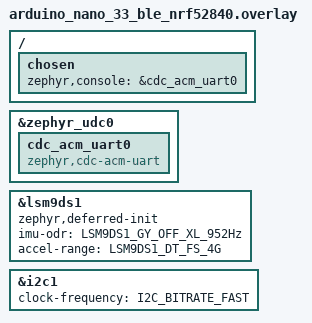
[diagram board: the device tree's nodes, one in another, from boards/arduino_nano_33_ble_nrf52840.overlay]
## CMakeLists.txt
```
# SPDX-License-Identifier: Apache-2.0
cmake_minimum_required(VERSION 3.20.0)

find_package(Zephyr REQUIRED HINTS $ENV{ZEPHYR_BASE})
project(vibration_monitor)

target_sources(app PRIVATE src/main.c src/accel_stats.c src/vib_fft.c src/ble_fmt.c src/ble_vib.c src/ble_sec.c src/ble_cmd.c)
```

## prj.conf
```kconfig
# Console over USB (CDC ACM), following Zephyr v4.4's samples/subsys/usb/console
CONFIG_GPIO=y
CONFIG_SERIAL=y
CONFIG_CONSOLE=y
CONFIG_UART_CONSOLE=y
CONFIG_STDOUT_CONSOLE=y
CONFIG_UART_LINE_CTRL=y

CONFIG_USB_DEVICE_STACK_NEXT=y
CONFIG_CDC_ACM_SERIAL_INITIALIZE_AT_BOOT=y
CONFIG_CDC_ACM_SERIAL_PRODUCT_STRING="Vibration monitor"

# Motion sensor (LSM9DS1, started by main.c with device_init)
CONFIG_SENSOR=y
CONFIG_I2C=y
CONFIG_REGULATOR=y

# FFT: CMSIS-DSP real FFT on the Cortex-M4F's floating-point unit
CONFIG_CMSIS_DSP=y
CONFIG_CMSIS_DSP_TRANSFORM=y
CONFIG_FPU=y
CONFIG_FPU_SHARING=y

# Bluetooth LE peripheral (custom GATT service in src/ble_vib.c)
CONFIG_BT=y
CONFIG_BT_PERIPHERAL=y
CONFIG_BT_DEVICE_NAME="VibMon Nano33"

# BLE security (step 8a): authenticated LE Secure Connections, passkey shown on
# the USB console.
CONFIG_BT_SMP=y
# Secure Connections Only mode: selects BT_SMP_SC_PAIR_ONLY, requires security
# level 4 and makes smp.c reject Just Works (unauthenticated) pairing.
CONFIG_BT_SMP_SC_ONLY=y
CONFIG_BT_SMP_ENFORCE_MITM=y
CONFIG_BT_BONDABLE=y
# Two phones may be paired; a third (who also needs the passkey) replaces the oldest.
CONFIG_BT_MAX_PAIRED=2
CONFIG_BT_KEYS_OVERWRITE_OLDEST=y
# Precaution (not measured): pairing callbacks run on the BT RX thread and print.
CONFIG_BT_RX_STACK_SIZE=2048

# Step 8b: pairing keys survive RESET. Settings stored with NVS in the board's
# free storage_partition (0xF8000, 32 KB), as in Zephyr's peripheral_hids sample.
CONFIG_BT_SETTINGS=y
CONFIG_SETTINGS=y
CONFIG_FLASH=y
CONFIG_FLASH_MAP=y
CONFIG_NVS=y
# Settings are written from the system work queue (the HIDS sample raises it too).
CONFIG_SYSTEM_WORKQUEUE_STACK_SIZE=2048

# Never enable CONFIG_BT_FIXED_PASSKEY or CONFIG_BT_SMP_ALLOW_UNAUTH_OVERWRITE:
# ble_sec.c refuses to build with the first.

# Threads: the sampler (priority 2) pre-empts the analysis in main (priority 7)
CONFIG_MAIN_THREAD_PRIORITY=7
# 3072 since step 8b: settings_load() (NVS) runs on this thread. Precaution, not measured.
CONFIG_MAIN_STACK_SIZE=3072

# No CONFIG_LOG: with the console on USB, immediate-mode logging from the USB
# stack itself goes through the USB link being set up.
```

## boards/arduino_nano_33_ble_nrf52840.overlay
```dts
/*
 * Board overlay for the Arduino Nano 33 BLE (rev1).
 *
 * 1. Console over USB (CDC ACM) instead of the UART on the header pins.
 *    Same pattern as Zephyr's snippets/cdc-acm-console; the board file
 *    already enables the USB device (zephyr_udc0 = &usbd).
 * 2. LSM9DS1 accelerometer ON. The binding's default output data rate is the
 *    power-up configuration, which is "IMU off" (0x00): without this the
 *    accelerometer reads zeros. Accelerometer 952 Hz (the application reads
 *    it at 400 Hz, so every read gets a fresh sample), gyroscope off, +-4 g.
 *    I2C at 400 kHz so one 6-byte read takes a fraction of the 2.5 ms period.
 * 3. zephyr,deferred-init: the driver is NOT started automatically at boot.
 *    main.c starts it with device_init() after the sensor supply has settled,
 *    and reports the result. (Started at boot it failed: "LSM9DS1 NOT READY".)
 */
#include <zephyr/dt-bindings/i2c/i2c.h>
#include <zephyr/dt-bindings/sensor/lsm9ds1.h>

/ {
	chosen {
		zephyr,console = &cdc_acm_uart0;
	};
};

&zephyr_udc0 {
	cdc_acm_uart0: cdc_acm_uart0 {
		compatible = "zephyr,cdc-acm-uart";
	};
};

&lsm9ds1 {
	zephyr,deferred-init;
	imu-odr = <LSM9DS1_GY_OFF_XL_952Hz>;
	accel-range = <LSM9DS1_DT_FS_4G>;
};

&i2c1 {
	clock-frequency = <I2C_BITRATE_FAST>;
};
```

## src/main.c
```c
/*
 * zephyr-ble-vibration-monitor - step 8: dominant vibration frequency (FFT),
 * sent over BLE (ble_vib.c) to paired phones only (ble_sec.c) as well as
 * printed on the USB console.
 *
 * Threads:
 *  - sampler (priority 2): reads the LSM9DS1 every 2.5 ms (400 Hz) from a
 *    kernel timer into one of two buffers (ping-pong). When a block of 512
 *    samples is full it hands the buffer to main through a message queue and
 *    carries on in the other buffer. It records the real sample rate, missed
 *    timer ticks, read errors and the slowest sensor read.
 *  - main (priority 7): start-up report, then for each block: CMSIS-DSP FFT
 *    (vib_fft.c), dominant frequency, amplitude and rms, printed over USB.
 * Block = 512 samples = 1.28 s; resolution 0.78 Hz; highest frequency 200 Hz.
 */
#include <stdbool.h>
#include <stdlib.h>
#include <zephyr/kernel.h>
#include <zephyr/device.h>
#include <zephyr/sys/atomic.h>
#include <zephyr/drivers/gpio.h>
#include <zephyr/drivers/i2c.h>
#include <zephyr/drivers/regulator.h>
#include <zephyr/drivers/sensor.h>
#include <zephyr/drivers/uart.h>
#include <zephyr/sys/printk.h>
#include <zephyr/version.h>
#include "vib_fft.h"
#include "ble_vib.h"

BUILD_ASSERT(DT_NODE_HAS_COMPAT(DT_CHOSEN(zephyr_console), zephyr_cdc_acm_uart),
	     "The console must be the USB CDC ACM UART (see the board overlay)");

#define SAMPLE_PERIOD_US 2500     /* 400 Hz */
#define HOST_WAIT_MS     30000    /* wait for a terminal at start-up */
#define MIN_FREQ_HZ      2.0f     /* ignore slow tilting and drift */
#define STILL_RMS        0.05f    /* m/s^2: below this the board counts as still */
#define SAMPLER_PRIO     2
#define SAMPLER_STACK    1024

#define IMU_NODE DT_NODELABEL(lsm9ds1)

static const struct gpio_dt_spec led = GPIO_DT_SPEC_GET(DT_ALIAS(led0), gpios);
static const struct device *const imu = DEVICE_DT_GET(IMU_NODE);
static const struct device *const i2c_bus = DEVICE_DT_GET(DT_BUS(IMU_NODE));
static const struct device *const vdd_env = DEVICE_DT_GET(DT_NODELABEL(vdd_env));

/* ---------------- shared between the sampler and main ---------------- */
struct block_info {
	int64_t ticks;          /* time from first to last sample, in system ticks */
	uint32_t errors;        /* failed sensor reads (previous value repeated) */
	uint32_t missed;        /* timer ticks the sampler was too late for */
	uint32_t max_read_us;   /* slowest sensor read in the block */
};

static int32_t raw[2][3][VIB_N];          /* milli-m/s^2 */
static struct block_info info[2];
static atomic_t busy[2];                   /* set while main owns the buffer */
static atomic_t overruns;                  /* blocks dropped because main was late */
K_MSGQ_DEFINE(block_q, sizeof(uint8_t), 2, 1);
K_TIMER_DEFINE(sample_timer, NULL, NULL);
K_THREAD_STACK_DEFINE(sampler_stack, SAMPLER_STACK);
static struct k_thread sampler_thread;

static int32_t to_milli(const struct sensor_value *v)
{
	return v->val1 * 1000 + v->val2 / 1000;
}

static void sampler(void *p1, void *p2, void *p3)
{
	ARG_UNUSED(p1); ARG_UNUSED(p2); ARG_UNUSED(p3);
	uint8_t w = 0;                 /* buffer being filled */
	bool storing = true;           /* false while both buffers are owned by main */
	uint32_t i = 0;
	int32_t last[3] = { 0, 0, 0 };
	int64_t t_first = 0;
	struct block_info cur = { 0 };

	k_timer_start(&sample_timer, K_USEC(SAMPLE_PERIOD_US), K_USEC(SAMPLE_PERIOD_US));
	while (1) {
		struct sensor_value v[3];
		uint32_t expired = k_timer_status_sync(&sample_timer);
		uint32_t c0 = k_cycle_get_32();

		if (expired > 1) {
			cur.missed += expired - 1;
		}
		if (sensor_sample_fetch_chan(imu, SENSOR_CHAN_ACCEL_XYZ) == 0 &&
		    sensor_channel_get(imu, SENSOR_CHAN_ACCEL_XYZ, v) == 0) {
			for (int a = 0; a < 3; a++) {
				last[a] = to_milli(&v[a]);
			}
		} else {
			cur.errors++;
		}
		uint32_t us = k_cyc_to_us_floor32(k_cycle_get_32() - c0);

		if (us > cur.max_read_us) {
			cur.max_read_us = us;
		}

		int64_t now = k_uptime_ticks();

		if (i == 0) {
			t_first = now;
		}
		if (storing) {
			for (int a = 0; a < 3; a++) {
				raw[w][a][i] = last[a];
			}
		}
		if (++i < VIB_N) {
			continue;
		}

		/* block complete */
		if (storing) {
			cur.ticks = now - t_first;
			info[w] = cur;
			atomic_set(&busy[w], 1);
			(void)k_msgq_put(&block_q, &w, K_NO_WAIT);
		} else {
			atomic_inc(&overruns);
		}
		uint8_t next = w ^ 1U;

		if (atomic_get(&busy[next]) == 0) {
			w = next;
			storing = true;
		} else {
			storing = false;   /* main still has both: skip this block */
		}
		i = 0;
		cur = (struct block_info){ 0 };
	}
}

/* ---------------- main: start-up report and analysis ---------------- */
static bool host_connected(const struct device *console)
{
	uint32_t dtr = 0;

	(void)uart_line_ctrl_get(console, UART_LINE_CTRL_DTR, &dtr);
	return dtr != 0;
}

/* prints v with 1 or 3 decimals, e.g. -0.512 */
static void print_f(float v, int decimals)
{
	long long scale = (decimals == 1) ? 10 : 1000;
	long long s = (long long)(v * (float)scale + (v >= 0.0f ? 0.5f : -0.5f));
	long long whole = llabs(s) / scale, frac = llabs(s) % scale;

	if (decimals == 1) {
		printk("%s%lld.%01lld", s < 0 ? "-" : "", whole, frac);
	} else {
		printk("%s%lld.%03lld", s < 0 ? "-" : "", whole, frac);
	}
}

static void probe(const char *name, uint16_t addr, uint8_t expect)
{
	uint8_t id = 0;
	int ret = i2c_reg_read_byte(i2c_bus, addr, 0x0F, &id);

	printk("  I2C 0x%02X %-13s WHO_AM_I: ", addr, name);
	if (ret == 0) {
		printk("0x%02X %s\n", id, id == expect ? "(correct)" : "(UNEXPECTED)");
	} else {
		printk("no answer (error %d)\n", ret);
	}
}

static bool start_sensor(void)
{
	int ret;

	printk("Sensor start-up report:\n");
	printk("  I2C bus %s: %s\n", i2c_bus->name, device_is_ready(i2c_bus) ? "ready" : "NOT READY");
	printk("  sensor supply (vdd_env): %s\n",
	       !device_is_ready(vdd_env) ? "regulator NOT READY" :
	       (regulator_is_enabled(vdd_env) ? "on" : "OFF"));
	probe("accel/gyro", 0x6B, 0x68);
	probe("magnetometer", 0x1E, 0x3D);
	ret = device_init(imu);
	printk("  device_init(lsm9ds1): %d %s\n", ret, ret == 0 ? "(started)" : "(FAILED)");
	return ret == 0 && device_is_ready(imu);
}

static void print_header(void)
{
	printk("every %u ms: dominant frequency | amplitude | rms (m/s^2) | real rate | fft time | "
	       "slowest read | missed / errors / dropped\n",
	       (unsigned int)(VIB_N * SAMPLE_PERIOD_US / 1000U));
}

int main(void)
{
	const struct device *const console = DEVICE_DT_GET(DT_CHOSEN(zephyr_console));
	bool led_ok = gpio_is_ready_dt(&led) &&
		      gpio_pin_configure_dt(&led, GPIO_OUTPUT_INACTIVE) == 0;
	static float fbuf[3][VIB_N];
	const float *const axes[3] = { fbuf[0], fbuf[1], fbuf[2] };
	bool host_seen;

	for (int waited = 0; waited < HOST_WAIT_MS && !host_connected(console); waited += 100) {
		if (led_ok && (waited % 500) == 0) {
			(void)gpio_pin_toggle_dt(&led);
		}
		k_msleep(100);
	}
	host_seen = host_connected(console);

	printk("\n=== zephyr-ble-vibration-monitor, step 8b ===\n");
	printk("Zephyr %s on %s, uptime %lld ms\n", KERNEL_VERSION_STRING, CONFIG_BOARD,
	       (long long)k_uptime_get());
	if (!start_sensor()) {
		printk("LSM9DS1 NOT READY - stopping here (see the report above)\n");
		return 0;
	}
	if (vib_fft_init() != VIB_OK) {
		printk("CMSIS-DSP FFT init FAILED - stopping here\n");
		return 0;
	}
	printk("LSM9DS1 READY. Sampling 400 Hz, blocks of %d (1.28 s), resolution 0.78 Hz, "
	       "up to 200 Hz; still below rms ", VIB_N);
	print_f(STILL_RMS, 3);
	printk(" m/s^2\n");
	int ble_err = ble_vib_init();

	if (ble_err == 0) {
		printk("BLE advertising as \"%s\" (service 5f2e0001-6d1b-4a3c-9b2e-7c4d1a2b3c4d)\n",
		       CONFIG_BT_DEVICE_NAME);
	} else {
		printk("BLE start FAILED (error %d) - continuing without it\n", ble_err);
	}
	print_header();

	k_thread_create(&sampler_thread, sampler_stack, K_THREAD_STACK_SIZEOF(sampler_stack),
			sampler, NULL, NULL, NULL, SAMPLER_PRIO, 0, K_NO_WAIT);
	k_thread_name_set(&sampler_thread, "sampler");

	uint16_t seq = 0;
	enum ble_vib_state ble_prev = BLE_VIB_OFF;

	while (1) {
		uint8_t b;
		struct block_info bi;
		struct vib_result r;
		enum ble_vib_state ble_now = ble_prev;   /* unchanged unless published */

		(void)k_msgq_get(&block_q, &b, K_FOREVER);
		for (int a = 0; a < 3; a++) {
			for (int i = 0; i < VIB_N; i++) {
				fbuf[a][i] = (float)raw[b][a][i] / 1000.0f;
			}
		}
		bi = info[b];
		atomic_set(&busy[b], 0);           /* copied: the sampler may reuse it */

		float fs = (bi.ticks > 0) ?
			(float)(VIB_N - 1) * (float)CONFIG_SYS_CLOCK_TICKS_PER_SEC / (float)bi.ticks : 0.0f;
		uint32_t c0 = k_cycle_get_32();
		int ret = vib_fft_analyse(axes, VIB_N, fs, MIN_FREQ_HZ, STILL_RMS, &r);
		uint32_t fft_us = k_cyc_to_us_floor32(k_cycle_get_32() - c0);

		if (ret == VIB_OK) {
			ble_now = ble_vib_publish(&r, seq++);
		}
		if (led_ok) {
			(void)gpio_pin_toggle_dt(&led);
		}
		if (!host_connected(console)) {
			ble_prev = ble_now;
			host_seen = false;
			continue;
		}
		if (!host_seen) {
			host_seen = true;
			printk("\n(terminal connected)\n");
			print_header();
		}
		if (ble_now != ble_prev) {
			printk("BLE: %s\n", ble_vib_state_str(ble_now));
			ble_prev = ble_now;
		}
		if (ret != VIB_OK) {
			printk("analysis error %d (rate ", ret);
			print_f(fs, 1);
			printk(" Hz)\n");
			continue;
		}
		if (r.active) {
			printk("f ");
			print_f(r.freq_hz, 1);
			printk(" Hz | amp ");
			print_f(r.amp, 3);
			printk(" | rms ");
			print_f(r.rms, 3);
		} else {
			printk("still        | rms ");
			print_f(r.rms, 3);
		}
		printk(" | ");
		print_f(fs, 1);
		printk(" Hz | fft %u us | read %u us | %u/%u/%u\n", (unsigned int)fft_us,
		       (unsigned int)bi.max_read_us, (unsigned int)bi.missed, (unsigned int)bi.errors,
		       (unsigned int)atomic_get(&overruns));
	}
	return 0;
}
```

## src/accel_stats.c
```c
/* accel_stats.c - see accel_stats.h */
#include "accel_stats.h"

uint32_t accel_isqrt64(uint64_t v)
{
	/* bit-by-bit method: exact, no floating point, bounded time */
	uint64_t res = 0;
	uint64_t bit = (uint64_t)1 << 62;

	while (bit > v) {
		bit >>= 2;
	}
	while (bit != 0) {
		if (v >= res + bit) {
			v -= res + bit;
			res = (res >> 1) + bit;
		} else {
			res >>= 1;
		}
		bit >>= 2;
	}
	return (uint32_t)res;
}

int32_t accel_magnitude(const int32_t v[3])
{
	uint64_t sq = 0;

	for (int i = 0; i < 3; i++) {
		int64_t c = v[i];
		sq += (uint64_t)(c * c);
	}
	return (int32_t)accel_isqrt64(sq);
}

void accel_stats_reset(struct accel_stats *s)
{
	for (int i = 0; i < 3; i++) {
		s->sum[i] = 0;
	}
	s->n = 0;
	s->mag_min = INT32_MAX;
	s->mag_max = 0;
}

void accel_stats_add(struct accel_stats *s, const int32_t v[3])
{
	int32_t m = accel_magnitude(v);

	for (int i = 0; i < 3; i++) {
		s->sum[i] += v[i];
	}
	s->n++;
	if (m < s->mag_min) {
		s->mag_min = m;
	}
	if (m > s->mag_max) {
		s->mag_max = m;
	}
}

int accel_stats_mean(const struct accel_stats *s, int32_t mean[3])
{
	if (s->n == 0) {
		return -1;
	}
	for (int i = 0; i < 3; i++) {
		mean[i] = (int32_t)(s->sum[i] / (int64_t)s->n);
	}
	return 0;
}
```

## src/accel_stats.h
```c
/*
 * accel_stats.h - integer statistics over a window of accelerometer samples.
 *
 * Units are milli-m/s^2 (1 g = 9807). Pure C, no Zephyr dependency, so it is
 * unit-tested on the PC (tests/host) before it runs on the board.
 */
#ifndef ACCEL_STATS_H
#define ACCEL_STATS_H

#include <stdint.h>

struct accel_stats {
	int64_t sum[3];       /* per-axis sum of samples */
	uint32_t n;           /* number of samples */
	int32_t mag_min;      /* smallest per-sample magnitude */
	int32_t mag_max;      /* largest per-sample magnitude */
};

/* Integer square root: largest r with r*r <= v. */
uint32_t accel_isqrt64(uint64_t v);

/* |v| in the same units, rounded down. */
int32_t accel_magnitude(const int32_t v[3]);

/* Start a new window: clear the sums and the count, and reset the magnitude range. */
void accel_stats_reset(struct accel_stats *s);
/* Add one sample v (x, y, z): updates the per-axis sums, the count and the smallest and largest magnitude. */
void accel_stats_add(struct accel_stats *s, const int32_t v[3]);

/* Per-axis mean (integer division, truncates toward zero). Returns -1 if empty. */
int accel_stats_mean(const struct accel_stats *s, int32_t mean[3]);

#endif
```

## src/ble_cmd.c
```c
/* ble_cmd.c - see ble_cmd.h */
#include "ble_cmd.h"

void ble_cmd_init(struct ble_cmd *c)
{
	c->armed = false;
	c->armed_ms = 0;
}

enum ble_cmd_action ble_cmd_feed(struct ble_cmd *c, int ch, uint32_t now_ms)
{
	if (c->armed && (uint32_t)(now_ms - c->armed_ms) >= BLE_CMD_CONFIRM_MS) {
		c->armed = false;           /* too late: a key now starts from scratch */
		if (ch < 0) {
			return BLE_CMD_TIMEOUT;
		}
	}
	if (ch < 0 || ch == '\r' || ch == '\n') {
		return BLE_CMD_NONE;
	}
	if (ch == 'U' || ch == 'u') {       /* (re-)arm, restarting the 5 s window */
		c->armed = true;
		c->armed_ms = now_ms;
		return BLE_CMD_ARMED;
	}
	if (c->armed) {
		c->armed = false;
		return (ch == 'Y' || ch == 'y') ? BLE_CMD_UNPAIR : BLE_CMD_CANCELLED;
	}
	return BLE_CMD_NONE;
}
```

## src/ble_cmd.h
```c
/*
 * ble_cmd.h - the two-key console command that forgets all paired phones.
 *
 * Pure C, no Zephyr: it only turns typed characters (and the passage of time)
 * into actions, so it can be tested on the PC.
 *
 *   U          arms the command ("forget ALL paired phones?")
 *   Y          within 5 s: confirm -> BLE_CMD_UNPAIR
 *   any other key, or 5 s of silence: cancel
 * Carriage return / line feed are ignored, so "U", Enter, "Y" also works.
 */
#ifndef BLE_CMD_H
#define BLE_CMD_H

#include <stdbool.h>
#include <stdint.h>

#define BLE_CMD_CONFIRM_MS 5000u

enum ble_cmd_action {
	BLE_CMD_NONE,       /* nothing to do */
	BLE_CMD_ARMED,      /* tell the person to press Y to confirm */
	BLE_CMD_UNPAIR,     /* confirmed: forget all paired phones now */
	BLE_CMD_CANCELLED,  /* a wrong key while armed */
	BLE_CMD_TIMEOUT,    /* nobody confirmed in time */
};

struct ble_cmd {
	bool armed;
	uint32_t armed_ms;
};

/* Start idle: not armed. */
void ble_cmd_init(struct ble_cmd *c);

/* ch: the typed character, or -1 if none arrived. now_ms: any free-running
 * millisecond counter (wrap-around at 2^32 is handled). Call it regularly,
 * also with ch = -1, so a timeout is noticed. */
enum ble_cmd_action ble_cmd_feed(struct ble_cmd *c, int ch, uint32_t now_ms);

#endif
```

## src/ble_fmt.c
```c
/* ble_fmt.c - see ble_fmt.h */
#include "ble_fmt.h"

#include <stdio.h>

/* round(v * scale), clamped to 0..max; NaN and negatives give 0 */
static uint32_t scaled(float v, float scale, uint32_t max)
{
	float s = v * scale + 0.5f;

	if (!(s > 0.0f)) {
		return 0;
	}
	if (s >= (float)max) {
		return max;
	}
	return (uint32_t)s;
}

static void put_le16(uint8_t *p, uint32_t v)
{
	p[0] = (uint8_t)(v & 0xFFU);
	p[1] = (uint8_t)((v >> 8) & 0xFFU);
}

void ble_meas_encode(const struct vib_result *r, uint16_t seq, uint8_t out[BLE_MEAS_LEN])
{
	out[0] = r->active ? 0x01U : 0x00U;
	put_le16(&out[1], r->active ? scaled(r->freq_hz, 10.0f, 0xFFFFU) : 0U);
	put_le16(&out[3], r->active ? scaled(r->amp, 1000.0f, 0xFFFFU) : 0U);
	put_le16(&out[5], scaled(r->rms, 1000.0f, 0xFFFFU));
	put_le16(&out[7], seq);
}

size_t ble_text_format(const struct vib_result *r, char out[BLE_TEXT_MAX + 1])
{
	int n;

	if (r->active) {
		uint32_t f = scaled(r->freq_hz, 10.0f, 9999U);    /* <= 999.9 Hz */
		uint32_t a = scaled(r->amp, 100.0f, 9999U);       /* <= 99.99 */
		uint32_t m = scaled(r->rms, 100.0f, 9999U);

		n = snprintf(out, BLE_TEXT_MAX + 1, "%u.%uHz %u.%02u %u.%02u",
			     (unsigned)(f / 10U), (unsigned)(f % 10U),
			     (unsigned)(a / 100U), (unsigned)(a % 100U),
			     (unsigned)(m / 100U), (unsigned)(m % 100U));
	} else {
		uint32_t m = scaled(r->rms, 1000.0f, 9999U);       /* <= 9.999 */

		n = snprintf(out, BLE_TEXT_MAX + 1, "still rms %u.%03u",
			     (unsigned)(m / 1000U), (unsigned)(m % 1000U));
	}
	if (n < 0) {
		out[0] = '\0';
		return 0;
	}
	return (size_t)n > BLE_TEXT_MAX ? BLE_TEXT_MAX : (size_t)n;
}
```

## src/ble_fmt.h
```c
/*
 * ble_fmt.h - what the BLE characteristics carry, as pure C so it is tested
 * on the PC (tests/host). No Zephyr or Bluetooth code here.
 *
 * Measurement characteristic, 9 bytes, little-endian:
 *   byte 0     flags   bit 0 = vibrating (0 = still)
 *   bytes 1-2  uint16  dominant frequency, 0.1 Hz units   (0 when still)
 *   bytes 3-4  uint16  amplitude, milli-m/s^2             (0 when still)
 *   bytes 5-6  uint16  rms, milli-m/s^2
 *   bytes 7-8  uint16  block sequence number (wraps)
 * Values are rounded and clamped to 0..65535.
 *
 * Summary characteristic: UTF-8 text, at most 20 bytes so it fits one
 * notification at the default ATT MTU, e.g. "24.6Hz 0.51 0.37" or
 * "still rms 0.025".
 */
#ifndef BLE_FMT_H
#define BLE_FMT_H

#include <stddef.h>
#include <stdint.h>
#include "vib_fft.h"

#define BLE_MEAS_LEN 9
#define BLE_TEXT_MAX 20

/* Encode r and the block sequence number seq into the 9-byte measurement; frequency and amplitude are 0 when r is not active. */
void ble_meas_encode(const struct vib_result *r, uint16_t seq, uint8_t out[BLE_MEAS_LEN]);

/* Writes the text (NUL-terminated) and returns its length (<= BLE_TEXT_MAX). */
size_t ble_text_format(const struct vib_result *r, char out[BLE_TEXT_MAX + 1]);

#endif
```

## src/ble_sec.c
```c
/* ble_sec.c - see ble_sec.h. API use checked against Zephyr v4.4.2:
 * include/zephyr/bluetooth/conn.h (bt_conn_auth_cb, bt_conn_auth_info_cb,
 * bt_security_err) and subsys/bluetooth/host/smp.c. */
#include "ble_sec.h"
#include "ble_cmd.h"

#include <zephyr/kernel.h>
#include <zephyr/device.h>
#include <zephyr/devicetree.h>
#include <zephyr/drivers/uart.h>
#include <zephyr/sys/printk.h>
#include <zephyr/bluetooth/bluetooth.h>
#include <zephyr/bluetooth/addr.h>
#include <zephyr/bluetooth/conn.h>

/* The security policy lives in prj.conf. If someone weakens it there, the
 * build must fail instead of silently shipping an open device. */
BUILD_ASSERT(IS_ENABLED(CONFIG_BT_SMP_SC_ONLY),
	     "step 8: prj.conf must set CONFIG_BT_SMP_SC_ONLY=y (authenticated LE Secure Connections)");
BUILD_ASSERT(IS_ENABLED(CONFIG_BT_SETTINGS),
	     "step 8b: prj.conf must set CONFIG_BT_SETTINGS=y (pairing keys kept in flash)");
BUILD_ASSERT(!IS_ENABLED(CONFIG_BT_FIXED_PASSKEY),
	     "step 8: CONFIG_BT_FIXED_PASSKEY must stay off (a fixed passkey is public)");

static const char *sec_err_str(enum bt_security_err err)
{
	switch (err) {
	case BT_SECURITY_ERR_SUCCESS:           return "ok";
	case BT_SECURITY_ERR_AUTH_FAIL:         return "authentication failed (wrong passkey?)";
	case BT_SECURITY_ERR_PIN_OR_KEY_MISSING: return "key missing (does this side still have the bond?)";
	case BT_SECURITY_ERR_OOB_NOT_AVAILABLE: return "OOB data not available";
	case BT_SECURITY_ERR_AUTH_REQUIREMENT:  return "required security level not reachable";
	case BT_SECURITY_ERR_PAIR_NOT_SUPPORTED: return "pairing not supported";
	case BT_SECURITY_ERR_PAIR_NOT_ALLOWED:  return "pairing not allowed";
	case BT_SECURITY_ERR_INVALID_PARAM:     return "invalid parameters";
	case BT_SECURITY_ERR_KEY_REJECTED:      return "distributed key rejected";
	case BT_SECURITY_ERR_UNSPECIFIED:       return "unspecified";
	default:                                return "unknown";
	}
}

static void peer_str(struct bt_conn *conn, char *buf, size_t len)
{
	bt_addr_le_to_str(bt_conn_get_dst(conn), buf, len);
}

/* Called by the stack when the phone must type a passkey. The value is
 * 0..999999 and has to be shown zero-padded to six digits (Zephyr's docs). */
static void passkey_display(struct bt_conn *conn, unsigned int passkey)
{
	char addr[BT_ADDR_LE_STR_LEN];

	peer_str(conn, addr, sizeof(addr));
	printk("\n*** BLE pairing request from %s ***\n"
	       "*** Passkey: %06u  - type it on the phone ***\n\n", addr, passkey);
}

/* Required whenever passkey_display is set: the stack tells us to stop showing it. */
static void auth_cancel(struct bt_conn *conn)
{
	char addr[BT_ADDR_LE_STR_LEN];

	peer_str(conn, addr, sizeof(addr));
	printk("BLE pairing cancelled (%s)\n", addr);
}

static const struct bt_conn_auth_cb auth_cb = {
	.passkey_display = passkey_display,
	.cancel = auth_cancel,
};

static void pairing_complete(struct bt_conn *conn, bool bonded)
{
	char addr[BT_ADDR_LE_STR_LEN];

	peer_str(conn, addr, sizeof(addr));
	printk("BLE pairing complete with %s (bonded: %s)\n", addr, bonded ? "yes" : "no");
}

static void pairing_failed(struct bt_conn *conn, enum bt_security_err reason)
{
	char addr[BT_ADDR_LE_STR_LEN];

	peer_str(conn, addr, sizeof(addr));
	printk("BLE pairing FAILED with %s: %s (code %d)\n", addr, sec_err_str(reason), (int)reason);
}

static void bond_deleted(uint8_t id, const bt_addr_le_t *peer)
{
	char addr[BT_ADDR_LE_STR_LEN];

	ARG_UNUSED(id);
	bt_addr_le_to_str(peer, addr, sizeof(addr));
	printk("BLE bond deleted for %s\n", addr);
}

static struct bt_conn_auth_info_cb auth_info_cb = {
	.pairing_complete = pairing_complete,
	.pairing_failed = pairing_failed,
	.bond_deleted = bond_deleted,
};

/* Level 4 = authenticated LE Secure Connections with a 128-bit key. Seeing it
 * again on a reconnection means the stored bond worked without a new passkey. */
static void security_changed(struct bt_conn *conn, bt_security_t level, enum bt_security_err err)
{
	char addr[BT_ADDR_LE_STR_LEN];

	peer_str(conn, addr, sizeof(addr));
	if (err == BT_SECURITY_ERR_SUCCESS) {
		printk("BLE link to %s is now at security level %d\n", addr, (int)level);
	} else {
		printk("BLE security change for %s failed: %s (code %d)\n",
		       addr, sec_err_str(err), (int)err);
	}
}

BT_CONN_CB_DEFINE(sec_conn_callbacks) = {
	.security_changed = security_changed,
};

int ble_sec_init(void)
{
	int err = bt_conn_auth_cb_register(&auth_cb);

	if (err) {
		return err;
	}
	return bt_conn_auth_info_cb_register(&auth_info_cb);
}

/* ---- step 8b: forgetting all paired phones from the USB console ---------- */

#define CMD_STACK_SIZE 2048    /* precaution: bt_unpair() ends in flash (NVS) writes */
#define CMD_PRIO       10      /* below main (7) and the sampler (2) */

static K_THREAD_STACK_DEFINE(cmd_stack, CMD_STACK_SIZE);
static struct k_thread cmd_thread_data;

static void cmd_thread(void *p1, void *p2, void *p3)
{
	const struct device *const console = DEVICE_DT_GET(DT_CHOSEN(zephyr_console));
	struct ble_cmd cmd;

	ARG_UNUSED(p1);
	ARG_UNUSED(p2);
	ARG_UNUSED(p3);
	ble_cmd_init(&cmd);
	if (!device_is_ready(console)) {
		return;
	}
	while (true) {
		unsigned char ch = 0;
		int c = (uart_poll_in(console, &ch) == 0) ? (int)ch : -1;

		switch (ble_cmd_feed(&cmd, c, k_uptime_get_32())) {
		case BLE_CMD_ARMED:
			printk("\nForget ALL paired phones? Press Y within %u s to confirm, any other key cancels.\n",
			       BLE_CMD_CONFIRM_MS / 1000u);
			break;
		case BLE_CMD_UNPAIR: {
			int err = bt_unpair(BT_ID_DEFAULT, BT_ADDR_LE_ANY);

			if (err) {
				printk("Forgetting the paired phones FAILED (error %d)\n", err);
			} else {
				printk("All paired phones forgotten. On each iPhone also use "
				       "Settings > Bluetooth > (i) > Forget This Device.\n");
			}
			break;
		}
		case BLE_CMD_CANCELLED:
			printk("Cancelled, nobody was forgotten.\n");
			break;
		case BLE_CMD_TIMEOUT:
			printk("No confirmation, nobody was forgotten.\n");
			break;
		default:
			break;
		}
		if (c < 0) {
			k_msleep(50);     /* nothing typed: poll again shortly */
		}
	}
}

static void count_bond(const struct bt_bond_info *info, void *user_data)
{
	ARG_UNUSED(info);
	(*(int *)user_data)++;
}

int ble_sec_start(void)
{
	int bonds = 0;
	k_tid_t tid;

	bt_foreach_bond(BT_ID_DEFAULT, count_bond, &bonds);
	printk("BLE: %d paired phone(s) restored from flash. Console: U then Y forgets them all.\n", bonds);

	tid = k_thread_create(&cmd_thread_data, cmd_stack, K_THREAD_STACK_SIZEOF(cmd_stack),
			      cmd_thread, NULL, NULL, NULL, CMD_PRIO, 0, K_NO_WAIT);
	k_thread_name_set(tid, "ble_cmd");
	return 0;
}
```

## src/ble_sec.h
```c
/*
 * ble_sec.h - the BLE pairing policy of the vibration monitor.
 *
 * The Nano 33 BLE has no display and no keyboard, so the USB console is the
 * display: during pairing a random 6-digit passkey is printed there and the
 * person types it into the phone. Only a phone that did this ends up with an
 * authenticated, encrypted link (LE Secure Connections, security level 4).
 * The GATT attributes in ble_vib.c demand that level, so an unpaired phone
 * can connect but cannot read or subscribe to anything.
 *
 * Step 8b: the pairing keys are stored in flash (Zephyr settings/NVS), so a
 * paired phone stays paired across a RESET. The USB console is also the
 * management interface: typing U then Y forgets every paired phone.
 */
#ifndef BLE_SEC_H
#define BLE_SEC_H

/* Registers the pairing callbacks. Call once, before or after bt_enable().
 * Returns 0 or a negative error code. */
int ble_sec_init(void);

/* Call after bt_enable() and settings_load(): reports how many paired phones
 * were restored from flash and starts the console command (U, then Y) that
 * forgets them all. Returns 0 or a negative error code. */
int ble_sec_start(void);

#endif
```

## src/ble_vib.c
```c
/* ble_vib.c - see ble_vib.h. API use follows Zephyr 4.4.2's
 * samples/bluetooth/peripheral and peripheral_hr. */
#include "ble_vib.h"
#include "ble_fmt.h"
#include "ble_sec.h"

#include <string.h>
#include <zephyr/kernel.h>
#include <zephyr/settings/settings.h>
#include <zephyr/sys/atomic.h>
#include <zephyr/sys/printk.h>
#include <zephyr/bluetooth/bluetooth.h>
#include <zephyr/bluetooth/conn.h>
#include <zephyr/bluetooth/gatt.h>
#include <zephyr/bluetooth/uuid.h>

/* Custom 128-bit UUIDs (randomly chosen base, ...0001 = service) */
#define VIB_SVC_UUID_VAL  BT_UUID_128_ENCODE(0x5f2e0001, 0x6d1b, 0x4a3c, 0x9b2e, 0x7c4d1a2b3c4d)
#define VIB_MEAS_UUID_VAL BT_UUID_128_ENCODE(0x5f2e0002, 0x6d1b, 0x4a3c, 0x9b2e, 0x7c4d1a2b3c4d)
#define VIB_TEXT_UUID_VAL BT_UUID_128_ENCODE(0x5f2e0003, 0x6d1b, 0x4a3c, 0x9b2e, 0x7c4d1a2b3c4d)

static const struct bt_uuid_128 svc_uuid = BT_UUID_INIT_128(VIB_SVC_UUID_VAL);
static const struct bt_uuid_128 meas_uuid = BT_UUID_INIT_128(VIB_MEAS_UUID_VAL);
static const struct bt_uuid_128 text_uuid = BT_UUID_INIT_128(VIB_TEXT_UUID_VAL);

/* latest values, read by the Bluetooth thread, written by main */
static struct k_spinlock lock;
static uint8_t meas_val[BLE_MEAS_LEN];
static char text_val[BLE_TEXT_MAX + 1] = "waiting";
static size_t text_len = 7;

static atomic_t meas_sub;      /* notifications enabled on the measurement */
static atomic_t text_sub;      /* ... on the text summary */
static atomic_t conn_count;
static atomic_t adv_needed;    /* advertising must be (re)started */
static bool started;

static ssize_t read_meas(struct bt_conn *conn, const struct bt_gatt_attr *attr,
			 void *buf, uint16_t len, uint16_t offset)
{
	uint8_t copy[BLE_MEAS_LEN];
	k_spinlock_key_t key = k_spin_lock(&lock);

	memcpy(copy, meas_val, sizeof(copy));
	k_spin_unlock(&lock, key);
	return bt_gatt_attr_read(conn, attr, buf, len, offset, copy, sizeof(copy));
}

static ssize_t read_text(struct bt_conn *conn, const struct bt_gatt_attr *attr,
			 void *buf, uint16_t len, uint16_t offset)
{
	char copy[BLE_TEXT_MAX + 1];
	size_t n;
	k_spinlock_key_t key = k_spin_lock(&lock);

	memcpy(copy, text_val, sizeof(copy));
	n = text_len;
	k_spin_unlock(&lock, key);
	return bt_gatt_attr_read(conn, attr, buf, len, offset, copy, (uint16_t)n);
}

static void meas_ccc_changed(const struct bt_gatt_attr *attr, uint16_t value)
{
	ARG_UNUSED(attr);
	atomic_set(&meas_sub, (value & BT_GATT_CCC_NOTIFY) ? 1 : 0);
}

static void text_ccc_changed(const struct bt_gatt_attr *attr, uint16_t value)
{
	ARG_UNUSED(attr);
	atomic_set(&text_sub, (value & BT_GATT_CCC_NOTIFY) ? 1 : 0);
}

/* Step 8: values and CCCs need an AUTHENTICATED link (pairing with a passkey,
 * see ble_sec.c). The label descriptors stay public: they reveal no data.
 * attrs: [0] service, [1] meas declaration, [2] meas value, [3] CCC, [4] CUD,
 *        [5] text declaration, [6] text value, [7] CCC, [8] CUD */
BT_GATT_SERVICE_DEFINE(vib_svc,
	BT_GATT_PRIMARY_SERVICE(&svc_uuid),
	BT_GATT_CHARACTERISTIC(&meas_uuid.uuid, BT_GATT_CHRC_READ | BT_GATT_CHRC_NOTIFY,
			       BT_GATT_PERM_READ_AUTHEN, read_meas, NULL, NULL),
	BT_GATT_CCC(meas_ccc_changed, BT_GATT_PERM_READ_AUTHEN | BT_GATT_PERM_WRITE_AUTHEN),
	BT_GATT_CUD("Vibration measurement", BT_GATT_PERM_READ),
	BT_GATT_CHARACTERISTIC(&text_uuid.uuid, BT_GATT_CHRC_READ | BT_GATT_CHRC_NOTIFY,
			       BT_GATT_PERM_READ_AUTHEN, read_text, NULL, NULL),
	BT_GATT_CCC(text_ccc_changed, BT_GATT_PERM_READ_AUTHEN | BT_GATT_PERM_WRITE_AUTHEN),
	BT_GATT_CUD("Summary (text)", BT_GATT_PERM_READ),
);
#define MEAS_VALUE_ATTR (&vib_svc.attrs[2])
#define TEXT_VALUE_ATTR (&vib_svc.attrs[6])

static const struct bt_data ad[] = {
	BT_DATA_BYTES(BT_DATA_FLAGS, (BT_LE_AD_GENERAL | BT_LE_AD_NO_BREDR)),
	BT_DATA_BYTES(BT_DATA_UUID128_ALL, VIB_SVC_UUID_VAL),
};

static const struct bt_data sd[] = {
	BT_DATA(BT_DATA_NAME_COMPLETE, CONFIG_BT_DEVICE_NAME, sizeof(CONFIG_BT_DEVICE_NAME) - 1),
};

static void connected(struct bt_conn *conn, uint8_t err)
{
	ARG_UNUSED(conn);
	if (err == 0) {
		atomic_inc(&conn_count);
	}
}

static void disconnected(struct bt_conn *conn, uint8_t reason)
{
	ARG_UNUSED(conn);
	ARG_UNUSED(reason);
	atomic_dec(&conn_count);
	atomic_set(&meas_sub, 0);
	atomic_set(&text_sub, 0);
	atomic_set(&adv_needed, 1);    /* restarted from ble_vib_publish() */
}

BT_CONN_CB_DEFINE(conn_callbacks) = {
	.connected = connected,
	.disconnected = disconnected,
};

static int start_advertising(void)
{
	int err = bt_le_adv_start(BT_LE_ADV_CONN_FAST_1, ad, ARRAY_SIZE(ad), sd, ARRAY_SIZE(sd));

	if (err == 0 || err == -EALREADY) {
		atomic_set(&adv_needed, 0);
		return 0;
	}
	return err;    /* e.g. connection object not freed yet: retried next block */
}

int ble_vib_init(void)
{
	int err;

	/* the notify calls below rely on these positions */
	if (bt_uuid_cmp(MEAS_VALUE_ATTR->uuid, &meas_uuid.uuid) != 0 ||
	    bt_uuid_cmp(TEXT_VALUE_ATTR->uuid, &text_uuid.uuid) != 0) {
		return -EINVAL;
	}
	err = ble_sec_init();    /* pairing callbacks: before anyone can connect */
	if (err) {
		return err;
	}
	err = bt_enable(NULL);
	if (err) {
		return err;
	}
	/* Step 8b: restore the pairing keys from flash. As in Zephyr's
	 * peripheral_hids sample this comes after bt_enable(). */
	if (IS_ENABLED(CONFIG_BT_SETTINGS)) {
		err = settings_load();
		if (err) {
			return err;
		}
	}
	err = ble_sec_start();
	if (err) {
		return err;
	}
	err = start_advertising();
	if (err) {
		return err;
	}
	started = true;
	return 0;
}

enum ble_vib_state ble_vib_publish(const struct vib_result *r, uint16_t seq)
{
	uint8_t m[BLE_MEAS_LEN];
	char t[BLE_TEXT_MAX + 1];
	size_t n;

	if (!started) {
		return BLE_VIB_OFF;
	}

	ble_meas_encode(r, seq, m);
	n = ble_text_format(r, t);

	k_spinlock_key_t key = k_spin_lock(&lock);

	memcpy(meas_val, m, sizeof(m));
	memcpy(text_val, t, sizeof(t));
	text_len = n;
	k_spin_unlock(&lock, key);

	if (atomic_get(&meas_sub)) {
		(void)bt_gatt_notify(NULL, MEAS_VALUE_ATTR, m, sizeof(m));
	}
	if (atomic_get(&text_sub)) {
		(void)bt_gatt_notify(NULL, TEXT_VALUE_ATTR, t, (uint16_t)n);
	}
	if (atomic_get(&adv_needed) && atomic_get(&conn_count) == 0) {
		(void)start_advertising();
	}

	if (atomic_get(&conn_count) <= 0) {
		return BLE_VIB_ADVERTISING;
	}
	return (atomic_get(&meas_sub) || atomic_get(&text_sub)) ? BLE_VIB_NOTIFYING : BLE_VIB_CONNECTED;
}

const char *ble_vib_state_str(enum ble_vib_state s)
{
	switch (s) {
	case BLE_VIB_ADVERTISING: return "advertising";
	case BLE_VIB_CONNECTED:   return "connected";
	case BLE_VIB_NOTIFYING:   return "notifying";
	default:                  return "off";
	}
}
```

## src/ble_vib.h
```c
/*
 * ble_vib.h - the vibration monitor's BLE peripheral: a custom GATT service
 * with two characteristics (binary measurement, text summary), both readable
 * and notifiable. Formats are in ble_fmt.h.
 */
#ifndef BLE_VIB_H
#define BLE_VIB_H

#include <stdint.h>
#include "vib_fft.h"

enum ble_vib_state {
	BLE_VIB_OFF,          /* Bluetooth not started */
	BLE_VIB_ADVERTISING,  /* waiting for a phone */
	BLE_VIB_CONNECTED,    /* connected, no notifications enabled */
	BLE_VIB_NOTIFYING,    /* connected and at least one characteristic subscribed */
};

/* Starts Bluetooth and advertising. Returns 0 or a negative error. */
int ble_vib_init(void);

/* Stores the latest result for reads, sends notifications to subscribers,
 * restarts advertising after a disconnection. Call once per analysed block. */
enum ble_vib_state ble_vib_publish(const struct vib_result *r, uint16_t seq);

/* Short text for a state, for the console log. Returns a constant string. */
const char *ble_vib_state_str(enum ble_vib_state s);

#endif
```

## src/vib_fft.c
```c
/* vib_fft.c - see vib_fft.h */
#include "vib_fft.h"

#include <math.h>
#include "arm_math.h"

static arm_rfft_fast_instance_f32 rfft;
static float window[VIB_N];
static float window_sum;
static float work[VIB_N];
static float spectrum[VIB_N];
static float power[VIB_BINS];
static bool ready;

int vib_fft_init(void)
{
	if (arm_rfft_fast_init_f32(&rfft, VIB_N) != ARM_MATH_SUCCESS) {
		ready = false;
		return VIB_ERR_INIT;
	}
	window_sum = 0.0f;
	for (uint32_t i = 0; i < VIB_N; i++) {
		/* periodic Hann window: the right choice for spectral analysis */
		window[i] = 0.5f * (1.0f - cosf(2.0f * PI * (float)i / (float)VIB_N));
		window_sum += window[i];
	}
	ready = true;
	return VIB_OK;
}

/* Hann window response at fractional bin offset d, relative to d = 0 */
static float hann_gain(float d)
{
	if (fabsf(d) < 1e-6f) {
		return 1.0f;
	}
	float sinc = sinf(PI * d) / (PI * d);

	return fabsf(sinc / (1.0f - d * d));
}

int vib_fft_analyse(const float *const axis[3], uint32_t n, float fs_hz, float min_hz,
		    float rms_threshold, struct vib_result *out)
{
	float sq_sum = 0.0f;

	if (!ready) {
		return VIB_ERR_INIT;
	}
	if (n != VIB_N || !(fs_hz > 0.0f) || min_hz < 0.0f || out == NULL) {
		return VIB_ERR_ARG;
	}

	for (uint32_t k = 0; k < VIB_BINS; k++) {
		power[k] = 0.0f;
	}

	for (int a = 0; a < 3; a++) {
		const float *x = axis[a];
		float mean = 0.0f;

		for (uint32_t i = 0; i < VIB_N; i++) {
			mean += x[i];
		}
		mean /= (float)VIB_N;
		for (uint32_t i = 0; i < VIB_N; i++) {
			float d = x[i] - mean;

			sq_sum += d * d;
			work[i] = d * window[i];
		}
		arm_rfft_fast_f32(&rfft, work, spectrum, 0);   /* note: modifies work[] */
		/* packed output: [0] = DC, [1] = Nyquist, then re/im pairs for bins 1..N/2-1 */
		for (uint32_t k = 1; k < VIB_BINS; k++) {
			float re = spectrum[2 * k];
			float im = spectrum[2 * k + 1];

			power[k] += re * re + im * im;
		}
	}

	out->rms = sqrtf(sq_sum / (float)VIB_N);
	out->active = out->rms >= rms_threshold;

	uint32_t kmin = (uint32_t)ceilf(min_hz * (float)VIB_N / fs_hz);
	uint32_t kmax = VIB_BINS - 2;          /* need a neighbour on each side */

	if (kmin < 2) {
		kmin = 2;                       /* skip DC and its leakage */
	}
	if (kmin > kmax) {
		return VIB_ERR_ARG;
	}

	uint32_t k = kmin;

	for (uint32_t i = kmin + 1; i <= kmax; i++) {
		if (power[i] > power[k]) {
			k = i;
		}
	}

	/* Gaussian interpolation: parabola through the logs of the magnitudes */
	float delta = 0.0f;
	float a = power[k - 1], b = power[k], c = power[k + 1];

	if (a > 0.0f && b > 0.0f && c > 0.0f) {
		float la = 0.5f * logf(a), lb = 0.5f * logf(b), lc = 0.5f * logf(c);
		float den = la - 2.0f * lb + lc;

		if (den < 0.0f) {
			delta = 0.5f * (la - lc) / den;
		}
		if (delta > 0.5f) {
			delta = 0.5f;
		} else if (delta < -0.5f) {
			delta = -0.5f;
		}
	}

	out->peak_bin = k;
	out->freq_hz = ((float)k + delta) * fs_hz / (float)VIB_N;
	/* single-sided amplitude of a sine: 2|X|/sum(w), corrected for the off-bin loss */
	out->amp = 2.0f * sqrtf(b) / (window_sum * hann_gain(delta));
	return VIB_OK;
}
```

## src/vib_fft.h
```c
/*
 * vib_fft.h - dominant vibration frequency from a block of 3-axis
 * accelerometer samples, using CMSIS-DSP's real FFT.
 *
 * Per axis: remove the mean (gravity and offset), apply a Hann window,
 * real FFT; the power spectra of the three axes are summed, so the result does
 * not depend on how the board is oriented. The peak bin is refined by
 * Gaussian (log-parabolic) interpolation, and the amplitude is corrected for
 * the Hann window's scalloping loss.
 *
 * Pure C + CMSIS-DSP: unit-tested on the PC (tests/host) with the same
 * CMSIS-DSP revision Zephyr uses. Not reentrant (static work buffers).
 */
#ifndef VIB_FFT_H
#define VIB_FFT_H

#include <stdbool.h>
#include <stdint.h>

#define VIB_N    512             /* samples per block (power of two) */
#define VIB_BINS (VIB_N / 2)

#define VIB_OK          0
#define VIB_ERR_INIT   -1        /* vib_fft_init() not called or failed */
#define VIB_ERR_ARG    -2        /* bad length, sample rate or frequency range */

struct vib_result {
	float rms;          /* m/s^2, vibration only (mean removed), all axes together */
	float freq_hz;      /* dominant frequency */
	float amp;          /* peak amplitude of that component, m/s^2 */
	uint32_t peak_bin;  /* FFT bin of the peak before interpolation */
	bool active;        /* rms >= threshold: false means "still" */
};

/* Prepare the FFT and the Hann window. Call once before vib_fft_analyse(). Returns VIB_OK or VIB_ERR_INIT. */
int vib_fft_init(void);

/*
 * axis[0..2]: VIB_N samples each (m/s^2), fs_hz: the real sample rate,
 * min_hz: ignore anything below (slow drift, tilting), rms_threshold: below
 * this the board counts as still.
 */
int vib_fft_analyse(const float *const axis[3], uint32_t n, float fs_hz, float min_hz,
		    float rms_threshold, struct vib_result *out);

#endif
```
